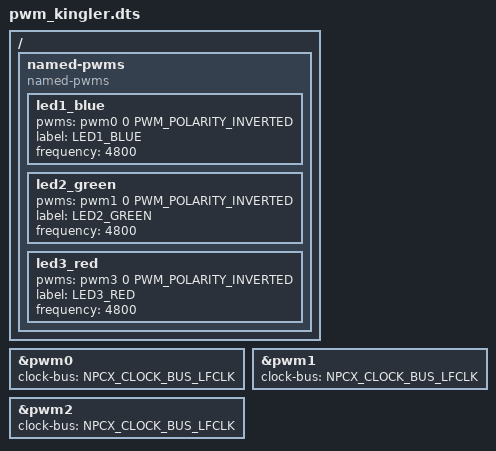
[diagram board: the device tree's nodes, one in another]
/* Copyright 2021 The Chromium OS Authors. All rights reserved.
 * Use of this source code is governed by a BSD-style license that can be
 * found in the LICENSE file.
 */

/ {
	named-pwms {
		compatible = "named-pwms";

		led1_blue: led1_blue {
			#pwm-cells = <0>;
			pwms = <&pwm0 0 PWM_POLARITY_INVERTED>;
			label = "LED1_BLUE";
			frequency = <4800>;
		};
		led2_green: led2_green  {
			#pwm-cells = <0>;
			pwms = <&pwm1 0 PWM_POLARITY_INVERTED>;
			label = "LED2_GREEN";
			frequency = <4800>;
		};
		led3_red: led3_red {
			#pwm-cells = <0>;
			pwms = <&pwm3 0 PWM_POLARITY_INVERTED>;
			label = "LED3_RED";
			frequency = <4800>;
		};
	};
};

/* Green LED */
&pwm0 {
	status = "okay";
	clock-bus = "NPCX_CLOCK_BUS_LFCLK";
};

/* Red LED */
&pwm1 {
	status = "okay";
	clock-bus = "NPCX_CLOCK_BUS_LFCLK";
};

/* Blue LED */
&pwm2 {
	status = "okay";
	clock-bus = "NPCX_CLOCK_BUS_LFCLK";
};
